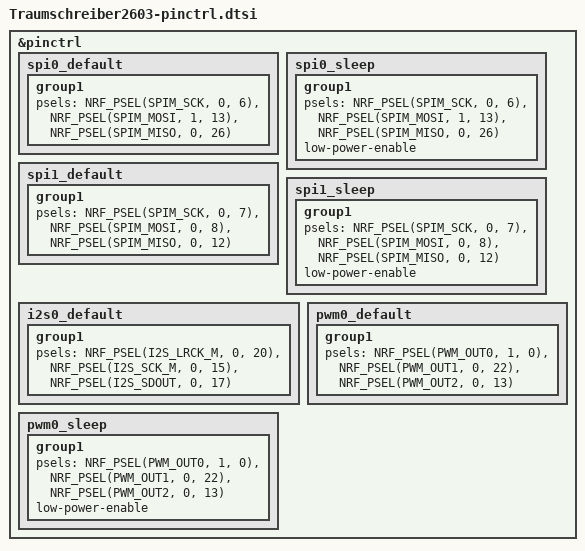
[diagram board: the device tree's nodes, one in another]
&pinctrl {
    /* SPI0 pins for ADS131M08 ADC */
    spi0_default: spi0_default {
        group1 {
            psels = <NRF_PSEL(SPIM_SCK, 0, 6)>, /* P0.06 - SCLK */
                    <NRF_PSEL(SPIM_MOSI, 1, 13)>, /* P1.13 - DIN */
                    <NRF_PSEL(SPIM_MISO, 0, 26)>; /* P0.26 - DOUT */
        };
    };

    spi0_sleep: spi0_sleep {
        group1 {
            psels = <NRF_PSEL(SPIM_SCK, 0, 6)>,
                    <NRF_PSEL(SPIM_MOSI, 1, 13)>,
                    <NRF_PSEL(SPIM_MISO, 0, 26)>;
            low-power-enable;
        };
    };


    /* Pins für die SPI1-Schnittstelle (microSD-Karte) */
    spi1_default: spi1_default {
        group1 {
            psels = <NRF_PSEL(SPIM_SCK, 0, 7)>, /* SCK an P0.07 */
                    <NRF_PSEL(SPIM_MOSI, 0, 8)>, /* MOSI an P0.08 */
                    <NRF_PSEL(SPIM_MISO, 0, 12)>;   /* MISO an P0.12 */
        };
    };

    spi1_sleep: spi1_sleep {
        group1 {
            psels = <NRF_PSEL(SPIM_SCK, 0, 7)>,
                    <NRF_PSEL(SPIM_MOSI, 0, 8)>,
                    <NRF_PSEL(SPIM_MISO, 0, 12)>;
            low-power-enable;
        };
    };

    i2s0_default: i2s0_default {
        group1 {
            psels = <NRF_PSEL(I2S_LRCK_M, 0, 20)>, /* P0.20 = LRCLK */
                    <NRF_PSEL(I2S_SCK_M, 0, 15)>, /* P0.15 = BCLK */
                    <NRF_PSEL(I2S_SDOUT, 0, 17)>;   /* P0.17 = DIN */
        };
    };

    /* PWM pins for RGB LED */
    pwm0_default: pwm0_default {
        group1 {
            psels = <NRF_PSEL(PWM_OUT0, 1, 0)>, /* Red LED */
                    <NRF_PSEL(PWM_OUT1, 0, 22)>, /* Green LED */
                    <NRF_PSEL(PWM_OUT2, 0, 13)>;  /* Blue LED */
        };
    };

    pwm0_sleep: pwm0_sleep {
        group1 {
            psels = <NRF_PSEL(PWM_OUT0, 1, 0)>,
                    <NRF_PSEL(PWM_OUT1, 0, 22)>,
                    <NRF_PSEL(PWM_OUT2, 0, 13)>;
            low-power-enable;
        };
    };
};
